VERSION ""

NS_ :

BS_:

BU_: BMS Third_Party_Device

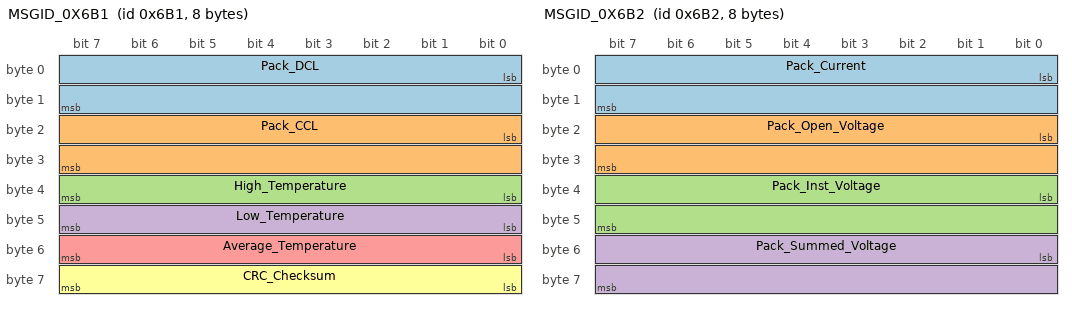
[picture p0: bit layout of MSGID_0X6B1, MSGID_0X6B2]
BO_ 1713 MSGID_0X6B1: 8 BMS
 SG_ Pack_DCL : 0|16@1+ (1.0,0) [0|0] "Amps"  Third_Party_Device
 SG_ Pack_CCL : 16|16@1+ (1.0,0) [0|0] "Amps"  Third_Party_Device
 SG_ High_Temperature : 39|8@0+ (1.0,0) [0|0] "Celsius"  Third_Party_Device
 SG_ Low_Temperature : 47|8@0+ (1.0,0) [0|0] "Celsius"  Third_Party_Device
 SG_ Average_Temperature : 55|8@0+ (1.0,0) [0|0] "Celsius"  Third_Party_Device
 SG_ CRC_Checksum : 63|8@0+ (1.0,1721) [0|0] ""  Third_Party_Device

BO_ 1714 MSGID_0X6B2: 8 BMS
 SG_ Pack_Current : 0|16@1- (0.1,0) [0|0] "Amps"  Third_Party_Device
 SG_ Pack_Open_Voltage : 16|16@1+ (0.1,0) [0|0] "Volts"  Third_Party_Device
 SG_ Pack_Inst_Voltage : 32|16@1+ (0.1,0) [0|0] "Volts"  Third_Party_Device
 SG_ Pack_Summed_Voltage : 48|16@1+ (0.01,0) [0|0] "Volts"  Third_Party_Device

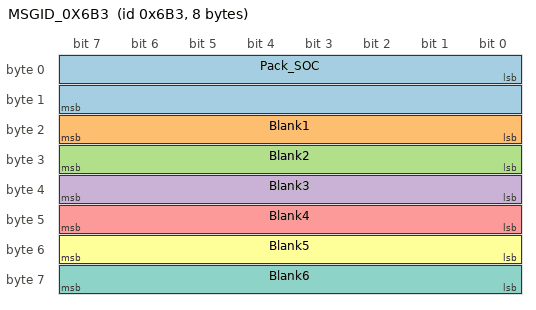
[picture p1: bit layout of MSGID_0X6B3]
BO_ 1715 MSGID_0X6B3: 8 BMS
 SG_ Pack_SOC : 0|16@1+ (0.5,0) [0|0] "Percent"  Third_Party_Device
 SG_ Blank1 : 23|8@0+ (1.0,0) [0|0] ""  Third_Party_Device
 SG_ Blank2 : 31|8@0+ (1.0,0) [0|0] ""  Third_Party_Device
 SG_ Blank3 : 39|8@0+ (1.0,0) [0|0] ""  Third_Party_Device
 SG_ Blank4 : 47|8@0+ (1.0,0) [0|0] ""  Third_Party_Device
 SG_ Blank5 : 55|8@0+ (1.0,0) [0|0] ""  Third_Party_Device
 SG_ Blank6 : 63|8@0+ (1.0,0) [0|0] ""  Third_Party_Device

CM_ BO_ 1713 "This ID Transmits at 104 ms.";
CM_ BO_ 1714 "This ID Transmits at 48 ms.";
CM_ BO_ 1715 "This ID Transmits at 1008 ms.";
